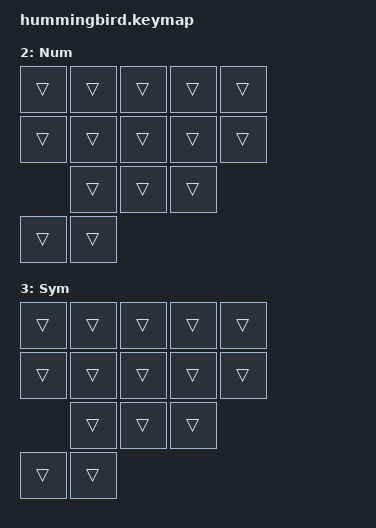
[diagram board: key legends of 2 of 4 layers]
/*
 * Copyright (c) 2022 The ZMK Contributors
 *
 * SPDX-License-Identifier: MIT
 */

#include <behaviors.dtsi>
#include <dt-bindings/zmk/keys.h>

#define DEF_L 0
#define NAV_L 1
#define NUM_L 2
#define SYM_L 3

// Using layer taps on thumbs, having quick tap as well helps w/ repeating space/backspace
&lt { quick-tap-ms = <200>; };

/ {
    behaviors {
        hm: homerow_mods {
            compatible = "zmk,behavior-hold-tap";
            #binding-cells = <2>;
            tapping-term-ms = <225>;
            flavor = "tap-preferred";
            bindings = <&kp>, <&kp>;
        };
    };

    combos {
        compatible = "zmk,combos";
        combo_z {
            timeout-ms = <50>;
            key-positions = <20 21>;
            bindings = <&kp Z>;
        };
        combo_b {
            timeout-ms = <50>;
            key-positions = <21 22>;
            bindings = <&kp B>;
        };

        combo_y {
            timeout-ms = <50>;
            key-positions = <23 24>;
            bindings = <&kp Y>;
        };

        combo_slash {
            timeout-ms = <50>;
            key-positions = <24 25>;
            bindings = <&kp SLASH>;
        };
    };

    keymap {
        compatible = "zmk,keymap";

        default_layer {
            bindings = <
                                                  &kp R           &trans       &lt NUM_L SPACE   
                                                                               


            >;
        };

        nav_layer {
            display-name = "Nav";
            bindings = <
                &trans     &trans     &trans      &trans          &trans       &trans                                              &trans
                &trans     &trans     &trans      &trans          &trans       &trans                                              &trans
                           &trans     &trans      &trans                                                       &trans   
                                                  &trans          &trans      
            >;
        };

        num_layer {
            display-name = "Num";
            bindings = <
                                                                                &trans          &trans         &trans      &trans     &trans
                                                                                &trans          &trans         &trans      &trans     &trans
                                                                                                &trans         &trans      &trans
                                                                                &trans          &trans
            >;
        };

        sym_layer {
            display-name = "Sym";
            bindings = <
                                                                                &trans          &trans         &trans      &trans     &trans
                                                                                &trans          &trans         &trans      &trans     &trans
                                                                                                &trans         &trans      &trans
                                                                                &trans          &trans
            >;
        };
    };
};
